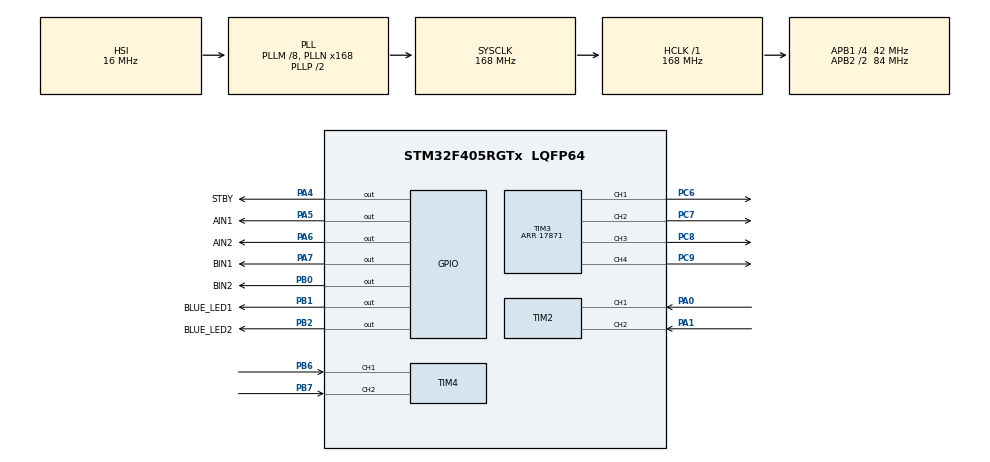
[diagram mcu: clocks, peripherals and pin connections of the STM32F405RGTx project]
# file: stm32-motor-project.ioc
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Mcu.Family=STM32F4
Mcu.Name=STM32F405RGTx
Mcu.Package=LQFP64
NVIC.PriorityGroup=NVIC_PRIORITYGROUP_4
PA0-WKUP.Signal=S_TIM2_CH1_ETR
PA1.Signal=S_TIM2_CH2
PA4.GPIO_Label=STBY
PA4.Signal=GPIO_Output
PA5.GPIO_Label=AIN1
PA5.Signal=GPIO_Output
PA6.GPIO_Label=AIN2
PA6.Signal=GPIO_Output
PA7.GPIO_Label=BIN1
PA7.Signal=GPIO_Output
PB0.GPIO_Label=BIN2
PB0.Signal=GPIO_Output
PB1.GPIO_Label=BLUE_LED1
PB1.Signal=GPIO_Output
PB2.GPIO_Label=BLUE_LED2
PB2.Signal=GPIO_Output
PB6.Signal=S_TIM4_CH1
PB7.Signal=S_TIM4_CH2
PC6.Signal=S_TIM3_CH1
PC7.Signal=S_TIM3_CH2
PC8.Signal=S_TIM3_CH3
PC9.Signal=S_TIM3_CH4
ProjectManager.HeapSize=0x200
ProjectManager.StackSize=0x400
ProjectManager.TargetToolchain=STM32CubeIDE
RCC.48MHZClocksFreq_Value=84000000
RCC.AHBFreq_Value=168000000
RCC.APB1CLKDivider=RCC_HCLK_DIV4
RCC.APB1Freq_Value=42000000
RCC.APB1TimFreq_Value=84000000
RCC.APB2CLKDivider=RCC_HCLK_DIV2
RCC.APB2Freq_Value=84000000
RCC.APB2TimFreq_Value=168000000
RCC.CortexFreq_Value=168000000
RCC.HCLKFreq_Value=168000000
RCC.HSE_VALUE=25000000
RCC.HSI_VALUE=16000000
RCC.LSE_VALUE=32768
RCC.PLLM=8
RCC.PLLN=168
RCC.SYSCLKFreq_VALUE=168000000
RCC.SYSCLKSource=RCC_SYSCLKSOURCE_PLLCLK
RCC.VCOOutputFreq_Value=336000000
SH.S_TIM2_CH1_ETR.0=TIM2_CH1,Encoder_Interface
SH.S_TIM2_CH2.0=TIM2_CH2,Encoder_Interface
SH.S_TIM3_CH1.0=TIM3_CH1,PWM Generation1 CH1
SH.S_TIM3_CH2.0=TIM3_CH2,PWM Generation2 CH2
SH.S_TIM3_CH3.0=TIM3_CH3,PWM Generation3 CH3
SH.S_TIM3_CH4.0=TIM3_CH4,PWM Generation4 CH4
SH.S_TIM4_CH1.0=TIM4_CH1,Encoder_Interface
SH.S_TIM4_CH2.0=TIM4_CH2,Encoder_Interface
TIM2.EncoderMode=TIM_ENCODERMODE_TI12
TIM3.Channel-PWM\ Generation1\ CH1=TIM_CHANNEL_1
TIM3.Channel-PWM\ Generation2\ CH2=TIM_CHANNEL_2
TIM3.Channel-PWM\ Generation3\ CH3=TIM_CHANNEL_3
TIM3.Channel-PWM\ Generation4\ CH4=TIM_CHANNEL_4
TIM3.Period=17871
TIM4.EncoderMode=TIM_ENCODERMODE_TI12
TIM6.Period=99
TIM6.Prescaler=8399
VP_TIM2_VS_OPM.Mode=OPM_bit
VP_TIM6_VS_ClockSourceINT.Mode=Enable_Timer
board=custom

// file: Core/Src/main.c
/* USER CODE BEGIN Header */
/**
  ******************************************************************************
  * @file           : main.c
  * @brief          : Main program body
  ******************************************************************************
  * @attention
  *
  * Copyright (c) 2026 STMicroelectronics.
  * All rights reserved.
  *
  * This software is licensed under terms that can be found in the LICENSE file
  * in the root directory of this software component.
  * If no LICENSE file comes with this software, it is provided AS-IS.
  *
  ******************************************************************************
  */
/* USER CODE END Header */
#include "main.h"
#include "tim.h"
#include "gpio.h"

/* USER CODE BEGIN Includes */
#include "motor.h"
/* USER CODE END Includes */

void SystemClock_Config(void);

int main(void)
{

  /* MCU Configuration--------------------------------------------------------*/

  /* Reset of all peripherals, Initializes the Flash interface and the Systick. */
  HAL_Init();

  /* Configure the system clock */
  SystemClock_Config();

  /* Initialize all configured peripherals */
  MX_GPIO_Init();
  MX_TIM2_Init();
  MX_TIM3_Init();
  MX_TIM4_Init();
  MX_TIM6_Init();
  /* USER CODE BEGIN 2 */
  Motor_Init();
  HAL_TIM_Base_Start_IT(&htim6);
  /* USER CODE END 2 */

  /* Infinite loop */
  /* USER CODE BEGIN WHILE */
  const float test_rpm[]   = { 50.0f, 150.0f, 250.0f, 0.0f };
  const uint8_t step_count = sizeof(test_rpm) / sizeof(test_rpm[0]);
  uint8_t step = 0;

  while (1)
  {
    /* USER CODE END WHILE */

    /* USER CODE BEGIN 3 */
    Motor_SetTargetRPM(&motor1, test_rpm[step]);
    Motor_SetTargetRPM(&motor2, test_rpm[step]);

    HAL_Delay(3000);

    step = (step + 1) % step_count;
  }
  /* USER CODE END 3 */
}

void SystemClock_Config(void)
{
  RCC_OscInitTypeDef RCC_OscInitStruct = {0};
  RCC_ClkInitTypeDef RCC_ClkInitStruct = {0};

  /** Configure the main internal regulator output voltage
  */
  __HAL_RCC_PWR_CLK_ENABLE();
  __HAL_PWR_VOLTAGESCALING_CONFIG(PWR_REGULATOR_VOLTAGE_SCALE1);

  /** Initializes the RCC Oscillators according to the specified parameters
  * in the RCC_OscInitTypeDef structure.
  */
  RCC_OscInitStruct.OscillatorType = RCC_OSCILLATORTYPE_HSI;
  RCC_OscInitStruct.HSIState = RCC_HSI_ON;
  RCC_OscInitStruct.HSICalibrationValue = RCC_HSICALIBRATION_DEFAULT;
  RCC_OscInitStruct.PLL.PLLState = RCC_PLL_ON;
  RCC_OscInitStruct.PLL.PLLSource = RCC_PLLSOURCE_HSI;
  RCC_OscInitStruct.PLL.PLLM = 8;
  RCC_OscInitStruct.PLL.PLLN = 168;
  RCC_OscInitStruct.PLL.PLLP = RCC_PLLP_DIV2;
  RCC_OscInitStruct.PLL.PLLQ = 4;
  if (HAL_RCC_OscConfig(&RCC_OscInitStruct) != HAL_OK)
  {
    Error_Handler();
  }

  /** Initializes the CPU, AHB and APB buses clocks
  */
  RCC_ClkInitStruct.ClockType = RCC_CLOCKTYPE_HCLK|RCC_CLOCKTYPE_SYSCLK
                              |RCC_CLOCKTYPE_PCLK1|RCC_CLOCKTYPE_PCLK2;
  RCC_ClkInitStruct.SYSCLKSource = RCC_SYSCLKSOURCE_PLLCLK;
  RCC_ClkInitStruct.AHBCLKDivider = RCC_SYSCLK_DIV1;
  RCC_ClkInitStruct.APB1CLKDivider = RCC_HCLK_DIV4;
  RCC_ClkInitStruct.APB2CLKDivider = RCC_HCLK_DIV2;

  if (HAL_RCC_ClockConfig(&RCC_ClkInitStruct, FLASH_LATENCY_5) != HAL_OK)
  {
    Error_Handler();
  }
}

/* USER CODE BEGIN 4 */
void HAL_TIM_PeriodElapsedCallback(TIM_HandleTypeDef *htim)
{
  if (htim->Instance == TIM6)
  {
    Motor_Update(&motor1);
    Motor_Update(&motor2);
  }
}
/* USER CODE END 4 */

void Error_Handler(void)
{
  __disable_irq();
  while (1)
  {
  }
}
